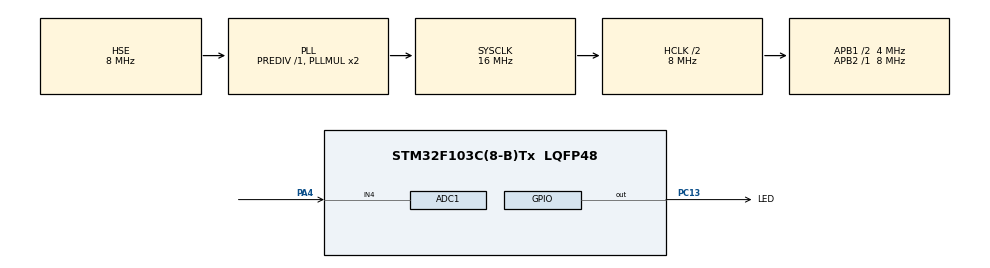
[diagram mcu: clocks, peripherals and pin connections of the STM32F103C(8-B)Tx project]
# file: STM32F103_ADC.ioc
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ADC1.Channel-3\#ChannelRegularConversion=ADC_CHANNEL_TEMPSENSOR
ADC1.EnableAnalogWatchDog=true
ADC1.InjNumberOfConversion=0
ADC1.NbrOfConversionFlag=1
ADC1.Rank-3\#ChannelRegularConversion=1
ADC1.SamplingTime-3\#ChannelRegularConversion=ADC_SAMPLETIME_1CYCLE_5
ADC1.WatchdogChannel=ADC_CHANNEL_TEMPSENSOR
ADC1.master=1
Mcu.Family=STM32F1
Mcu.Name=STM32F103C(8-B)Tx
Mcu.Package=LQFP48
NVIC.ADC1_2_IRQn=true\:0\:0\:false\:false\:true\:true\:true
NVIC.PriorityGroup=NVIC_PRIORITYGROUP_4
PA13.Mode=Serial_Wire
PA13.Signal=SYS_JTMS-SWDIO
PA14.Mode=Serial_Wire
PA14.Signal=SYS_JTCK-SWCLK
PA4.Signal=ADCx_IN4
PC13-TAMPER-RTC.GPIO_Label=LED
PC13-TAMPER-RTC.Signal=GPIO_Output
PD0-OSC_IN.Mode=HSE-External-Oscillator
PD0-OSC_IN.Signal=RCC_OSC_IN
PD1-OSC_OUT.Mode=HSE-External-Oscillator
PD1-OSC_OUT.Signal=RCC_OSC_OUT
ProjectManager.HeapSize=0x200
ProjectManager.StackSize=0x400
ProjectManager.TargetToolchain=TrueSTUDIO
RCC.ADCPresc=RCC_ADCPCLK2_DIV4
RCC.AHBCLKDivider=RCC_SYSCLK_DIV2
RCC.AHBFreq_Value=8000000
RCC.APB1CLKDivider=RCC_HCLK_DIV2
RCC.APB1Freq_Value=4000000
RCC.APB1TimFreq_Value=8000000
RCC.APB2Freq_Value=8000000
RCC.APB2TimFreq_Value=8000000
RCC.HCLKFreq_Value=8000000
RCC.PLLSourceVirtual=RCC_PLLSOURCE_HSE
RCC.SYSCLKFreq_VALUE=16000000
RCC.SYSCLKSource=RCC_SYSCLKSOURCE_PLLCLK
RCC.USBFreq_Value=16000000
SH.ADCx_IN4.0=ADC1_IN4,IN4
VP_ADC1_TempSens_Input.Mode=IN-TempSens
board=custom

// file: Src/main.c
/* USER CODE BEGIN Header */
/**
  ******************************************************************************
  * @file           : main.c
  * @brief          : Main program body
  ******************************************************************************
  * @attention
  *
  * <h2><center>&copy; Copyright (c) 2019 STMicroelectronics.
  * All rights reserved.</center></h2>
  *
  * This software component is licensed by ST under BSD 3-Clause license,
  * the "License"; You may not use this file except in compliance with the
  * License. You may obtain a copy of the License at:
  *                        opensource.org/licenses/BSD-3-Clause
  *
  ******************************************************************************
  */
/* USER CODE END Header */

#include "main.h"
#include "adc.h"
#include "gpio.h"

/* USER CODE BEGIN PV */
ADC_HandleTypeDef hadc1;
volatile uint32_t value;
uint16_t PomiarADC;
/* USER CODE END PV */

void SystemClock_Config(void);

int main(void)
{

  /* MCU Configuration--------------------------------------------------------*/

  /* Reset of all peripherals, Initializes the Flash interface and the Systick. */
  HAL_Init();

  /* Configure the system clock */
  SystemClock_Config();

  /* Initialize all configured peripherals */
  MX_GPIO_Init();
  MX_ADC1_Init();
  /* USER CODE BEGIN 2 */
  HAL_ADC_Stop(&hadc1);
  HAL_ADCEx_Calibration_Start(&hadc1);
  HAL_ADC_Start(&hadc1);

  /* USER CODE END 2 */

  /* Infinite loop */
  while (1)
  {

    /* USER CODE BEGIN 3 */

 value = HAL_ADC_GetValue(&hadc1);

  HAL_GPIO_TogglePin(GPIOC, GPIO_PIN_13);//LED8
  HAL_Delay(500);
  /* USER CODE END 3 */
}
}
void SystemClock_Config(void)
{
  RCC_OscInitTypeDef RCC_OscInitStruct = {0};
  RCC_ClkInitTypeDef RCC_ClkInitStruct = {0};
  RCC_PeriphCLKInitTypeDef PeriphClkInit = {0};

  /** Initializes the CPU, AHB and APB busses clocks
  */
  RCC_OscInitStruct.OscillatorType = RCC_OSCILLATORTYPE_HSE;
  RCC_OscInitStruct.HSEState = RCC_HSE_ON;
  RCC_OscInitStruct.HSEPredivValue = RCC_HSE_PREDIV_DIV1;
  RCC_OscInitStruct.HSIState = RCC_HSI_ON;
  RCC_OscInitStruct.PLL.PLLState = RCC_PLL_ON;
  RCC_OscInitStruct.PLL.PLLSource = RCC_PLLSOURCE_HSE;
  RCC_OscInitStruct.PLL.PLLMUL = RCC_PLL_MUL2;
  if (HAL_RCC_OscConfig(&RCC_OscInitStruct) != HAL_OK)
  {
    Error_Handler();
  }
  /** Initializes the CPU, AHB and APB busses clocks
  */
  RCC_ClkInitStruct.ClockType = RCC_CLOCKTYPE_HCLK|RCC_CLOCKTYPE_SYSCLK
                              |RCC_CLOCKTYPE_PCLK1|RCC_CLOCKTYPE_PCLK2;
  RCC_ClkInitStruct.SYSCLKSource = RCC_SYSCLKSOURCE_PLLCLK;
  RCC_ClkInitStruct.AHBCLKDivider = RCC_SYSCLK_DIV2;
  RCC_ClkInitStruct.APB1CLKDivider = RCC_HCLK_DIV2;
  RCC_ClkInitStruct.APB2CLKDivider = RCC_HCLK_DIV1;

  if (HAL_RCC_ClockConfig(&RCC_ClkInitStruct, FLASH_LATENCY_0) != HAL_OK)
  {
    Error_Handler();
  }
  PeriphClkInit.PeriphClockSelection = RCC_PERIPHCLK_ADC;
  PeriphClkInit.AdcClockSelection = RCC_ADCPCLK2_DIV4;
  if (HAL_RCCEx_PeriphCLKConfig(&PeriphClkInit) != HAL_OK)
  {
    Error_Handler();
  }
}

void Error_Handler(void)
{
}

/************************ (C) COPYRIGHT STMicroelectronics *****END OF FILE****/
